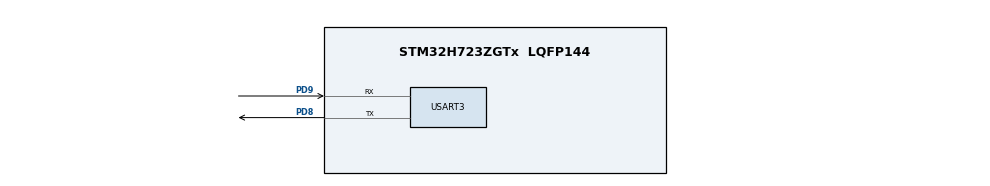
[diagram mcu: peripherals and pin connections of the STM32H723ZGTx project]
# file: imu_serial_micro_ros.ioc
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CORTEX_M7.AccessPermission_S-Cortex_Memory_Protection_Unit_Region1_Settings_S=MPU_REGION_FULL_ACCESS
CORTEX_M7.BaseAddress_S-Cortex_Memory_Protection_Unit_Region1_Settings_S=0x24000000
CORTEX_M7.CPU_DCache=Enabled
CORTEX_M7.CPU_ICache=Enabled
CORTEX_M7.Enable_S-Cortex_Memory_Protection_Unit_Region1_Settings_S=MPU_REGION_ENABLE
CORTEX_M7.Size_S-Cortex_Memory_Protection_Unit_Region1_Settings_S=MPU_REGION_SIZE_16KB
CORTEX_M7.TypeExtField_S-Cortex_Memory_Protection_Unit_Region1_Settings_S=MPU_TEX_LEVEL1
CORTEX_M7.default_mode_Activation=1
Dma.Request0=USART3_RX
Dma.Request1=USART3_TX
Dma.USART3_RX.0.Direction=DMA_PERIPH_TO_MEMORY
Dma.USART3_RX.0.EventEnable=DISABLE
Dma.USART3_RX.0.FIFOMode=DMA_FIFOMODE_DISABLE
Dma.USART3_RX.0.Instance=DMA1_Stream0
Dma.USART3_RX.0.MemDataAlignment=DMA_MDATAALIGN_BYTE
Dma.USART3_RX.0.MemInc=DMA_MINC_ENABLE
Dma.USART3_RX.0.Mode=DMA_CIRCULAR
Dma.USART3_RX.0.PeriphDataAlignment=DMA_PDATAALIGN_BYTE
Dma.USART3_RX.0.PeriphInc=DMA_PINC_DISABLE
Dma.USART3_RX.0.Polarity=HAL_DMAMUX_REQ_GEN_RISING
Dma.USART3_RX.0.Priority=DMA_PRIORITY_VERY_HIGH
Dma.USART3_RX.0.RequestNumber=1
Dma.USART3_RX.0.SignalID=NONE
Dma.USART3_RX.0.SyncEnable=DISABLE
Dma.USART3_RX.0.SyncPolarity=HAL_DMAMUX_SYNC_NO_EVENT
Dma.USART3_RX.0.SyncRequestNumber=1
Dma.USART3_RX.0.SyncSignalID=NONE
Dma.USART3_TX.1.Direction=DMA_MEMORY_TO_PERIPH
Dma.USART3_TX.1.EventEnable=DISABLE
Dma.USART3_TX.1.FIFOMode=DMA_FIFOMODE_DISABLE
Dma.USART3_TX.1.Instance=DMA1_Stream1
Dma.USART3_TX.1.MemDataAlignment=DMA_MDATAALIGN_BYTE
Dma.USART3_TX.1.MemInc=DMA_MINC_ENABLE
Dma.USART3_TX.1.Mode=DMA_NORMAL
Dma.USART3_TX.1.PeriphDataAlignment=DMA_PDATAALIGN_BYTE
Dma.USART3_TX.1.PeriphInc=DMA_PINC_DISABLE
Dma.USART3_TX.1.Polarity=HAL_DMAMUX_REQ_GEN_RISING
Dma.USART3_TX.1.Priority=DMA_PRIORITY_VERY_HIGH
Dma.USART3_TX.1.RequestNumber=1
Dma.USART3_TX.1.SignalID=NONE
Dma.USART3_TX.1.SyncEnable=DISABLE
Dma.USART3_TX.1.SyncPolarity=HAL_DMAMUX_SYNC_NO_EVENT
Dma.USART3_TX.1.SyncRequestNumber=1
Dma.USART3_TX.1.SyncSignalID=NONE
FREERTOS.Tasks01=defaultTask,24,3000,StartDefaultTask,Default,NULL,Dynamic,NULL,NULL
Mcu.Family=STM32H7
Mcu.Name=STM32H723ZGTx
Mcu.Package=LQFP144
NUCLEO-H723ZG.BUTTON=1
NUCLEO-H723ZG.LD1=true
NUCLEO-H723ZG.LD2=true
NUCLEO-H723ZG.LD3=true
NUCLEO-H723ZG.VCP=false
NVIC.DMA1_Stream0_IRQn=true\:5\:0\:false\:false\:true\:true\:false\:true\:true
NVIC.DMA1_Stream1_IRQn=true\:5\:0\:false\:false\:true\:true\:false\:true\:true
NVIC.EXTI15_10_IRQn=true\:5\:0\:false\:false\:true\:true\:false\:true\:true
NVIC.PriorityGroup=NVIC_PRIORITYGROUP_4
NVIC.TIM1_UP_IRQn=true\:15\:0\:false\:false\:true\:false\:false\:true\:true
NVIC.TimeBase=TIM1_UP_IRQn
NVIC.TimeBaseIP=TIM1
NVIC.USART3_IRQn=true\:5\:0\:false\:false\:true\:true\:true\:true\:true
PA13(JTMS/SWDIO).GPIO_Label=SWDIO
PA13(JTMS/SWDIO).Signal=DEBUG_JTMS-SWDIO
PA14(JTCK/SWCLK).GPIO_Label=SWCLK
PA14(JTCK/SWCLK).Signal=DEBUG_JTCK-SWCLK
PC14-OSC32_IN.Signal=RCC_OSC32_IN
PC15-OSC32_OUT.Signal=RCC_OSC32_OUT
PD8.Mode=Asynchronous
PD8.Signal=USART3_TX
PD9.Mode=Asynchronous
PD9.Signal=USART3_RX
PH0-OSC_IN.Mode=HSE-External-Oscillator
PH0-OSC_IN.Signal=RCC_OSC_IN
PH1-OSC_OUT.Mode=HSE-External-Oscillator
PH1-OSC_OUT.Signal=RCC_OSC_OUT
ProjectManager.HeapSize=0x200
ProjectManager.StackSize=0x400
ProjectManager.TargetToolchain=STM32CubeIDE
RCC.ADCFreq_Value=608000000
RCC.APB1Freq_Value=137500000
RCC.APB2Freq_Value=137500000
RCC.APB3Freq_Value=137500000
RCC.APB4Freq_Value=137500000
RCC.CortexFreq_Value=550000000
RCC.D1PPRE=RCC_APB3_DIV2
RCC.D2PPRE1=RCC_APB1_DIV2
RCC.D2PPRE2=RCC_APB2_DIV2
RCC.D3PPRE=RCC_APB4_DIV2
RCC.DIVM1=4
RCC.DIVM2=1
RCC.DIVN1=34
RCC.DIVN2=19
RCC.DIVP1=1
RCC.DIVQ1=4
RCC.HCLKFreq_Value=275000000
RCC.HPRE=RCC_HCLK_DIV2
RCC.HSE_VALUE=8000000
RCC.PLLFRACN=3072
RCC.SYSCLKFreq_VALUE=550000000
RCC.SYSCLKSource=RCC_SYSCLKSOURCE_PLLCLK
RCC.USBCLockSelection=RCC_USBCLKSOURCE_HSI48
RCC.USBFreq_Value=48000000
USART3.VirtualMode-Asynchronous=VM_ASYNC
VP_FREERTOS_VS_CMSIS_V2.Mode=CMSIS_V2
VP_MEMORYMAP_VS_MEMORYMAP.Mode=CurAppReg
VP_NUCLEO-H723ZG_VS_BSP_COMMON.Mode=COMMON
VP_SYS_VS_tim1.Mode=TIM1
board=NUCLEO-H723ZG

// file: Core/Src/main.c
/* USER CODE BEGIN Header */
/**
  ******************************************************************************
  * @file           : main.c
  * @brief          : Main program body
  ******************************************************************************
  * @attention
  *
  * Copyright (c) 2026 STMicroelectronics.
  * All rights reserved.
  *
  * This software is licensed under terms that can be found in the LICENSE file
  * in the root directory of this software component.
  * If no LICENSE file comes with this software, it is provided AS-IS.
  *
  ******************************************************************************
  */
/* USER CODE END Header */
#include "main.h"
#include "cmsis_os.h"
#include "dma.h"
#include "usart.h"
#include "gpio.h"

void SystemClock_Config(void);
static void MPU_Config(void);
void MX_FREERTOS_Init(void);

int main(void)
{

  /* MPU Configuration--------------------------------------------------------*/
  MPU_Config();

  /* Enable the CPU Cache */

  /* Enable I-Cache---------------------------------------------------------*/
  SCB_EnableICache();

  /* Enable D-Cache---------------------------------------------------------*/
  SCB_EnableDCache();

  /* MCU Configuration--------------------------------------------------------*/

  /* Reset of all peripherals, Initializes the Flash interface and the Systick. */
  HAL_Init();

  /* Configure the system clock */
  SystemClock_Config();

  /* Initialize all configured peripherals */
  MX_GPIO_Init();
  MX_DMA_Init();
  MX_USART3_UART_Init();

  /* Init scheduler */
  osKernelInitialize();  /* Call init function for freertos objects (in cmsis_os2.c) */
  MX_FREERTOS_Init();

  /* Initialize leds */
  BSP_LED_Init(LED_GREEN);
  BSP_LED_Init(LED_YELLOW);
  BSP_LED_Init(LED_RED);

  /* Initialize USER push-button, will be used to trigger an interrupt each time it's pressed.*/
  BSP_PB_Init(BUTTON_USER, BUTTON_MODE_EXTI);

  /* Start scheduler */
  osKernelStart();

  /* We should never get here as control is now taken by the scheduler */

  /* Infinite loop */
  while (1)
  {

  }
}

void SystemClock_Config(void)
{
  RCC_OscInitTypeDef RCC_OscInitStruct = {0};
  RCC_ClkInitTypeDef RCC_ClkInitStruct = {0};

  /** Supply configuration update enable
  */
  HAL_PWREx_ConfigSupply(PWR_LDO_SUPPLY);

  /** Configure the main internal regulator output voltage
  */
  __HAL_PWR_VOLTAGESCALING_CONFIG(PWR_REGULATOR_VOLTAGE_SCALE0);

  while(!__HAL_PWR_GET_FLAG(PWR_FLAG_VOSRDY)) {}

  /** Initializes the RCC Oscillators according to the specified parameters
  * in the RCC_OscInitTypeDef structure.
  */
  RCC_OscInitStruct.OscillatorType = RCC_OSCILLATORTYPE_HSI;
  RCC_OscInitStruct.HSIState = RCC_HSI_DIV1;
  RCC_OscInitStruct.HSICalibrationValue = 64;
  RCC_OscInitStruct.PLL.PLLState = RCC_PLL_ON;
  RCC_OscInitStruct.PLL.PLLSource = RCC_PLLSOURCE_HSI;
  RCC_OscInitStruct.PLL.PLLM = 4;
  RCC_OscInitStruct.PLL.PLLN = 34;
  RCC_OscInitStruct.PLL.PLLP = 1;
  RCC_OscInitStruct.PLL.PLLQ = 4;
  RCC_OscInitStruct.PLL.PLLR = 2;
  RCC_OscInitStruct.PLL.PLLRGE = RCC_PLL1VCIRANGE_3;
  RCC_OscInitStruct.PLL.PLLVCOSEL = RCC_PLL1VCOWIDE;
  RCC_OscInitStruct.PLL.PLLFRACN = 3072;
  if (HAL_RCC_OscConfig(&RCC_OscInitStruct) != HAL_OK)
  {
    Error_Handler();
  }

  /** Initializes the CPU, AHB and APB buses clocks
  */
  RCC_ClkInitStruct.ClockType = RCC_CLOCKTYPE_HCLK|RCC_CLOCKTYPE_SYSCLK
                              |RCC_CLOCKTYPE_PCLK1|RCC_CLOCKTYPE_PCLK2
                              |RCC_CLOCKTYPE_D3PCLK1|RCC_CLOCKTYPE_D1PCLK1;
  RCC_ClkInitStruct.SYSCLKSource = RCC_SYSCLKSOURCE_PLLCLK;
  RCC_ClkInitStruct.SYSCLKDivider = RCC_SYSCLK_DIV1;
  RCC_ClkInitStruct.AHBCLKDivider = RCC_HCLK_DIV2;
  RCC_ClkInitStruct.APB3CLKDivider = RCC_APB3_DIV2;
  RCC_ClkInitStruct.APB1CLKDivider = RCC_APB1_DIV2;
  RCC_ClkInitStruct.APB2CLKDivider = RCC_APB2_DIV2;
  RCC_ClkInitStruct.APB4CLKDivider = RCC_APB4_DIV2;

  if (HAL_RCC_ClockConfig(&RCC_ClkInitStruct, FLASH_LATENCY_3) != HAL_OK)
  {
    Error_Handler();
  }
}

 /* MPU Configuration */

void MPU_Config(void)
{
  MPU_Region_InitTypeDef MPU_InitStruct = {0};

  /* Disables the MPU */
  HAL_MPU_Disable();

  /** Initializes and configures the Region and the memory to be protected
  */
  MPU_InitStruct.Enable = MPU_REGION_ENABLE;
  MPU_InitStruct.Number = MPU_REGION_NUMBER0;
  MPU_InitStruct.BaseAddress = 0x0;
  MPU_InitStruct.Size = MPU_REGION_SIZE_4GB;
  MPU_InitStruct.SubRegionDisable = 0x87;
  MPU_InitStruct.TypeExtField = MPU_TEX_LEVEL0;
  MPU_InitStruct.AccessPermission = MPU_REGION_NO_ACCESS;
  MPU_InitStruct.DisableExec = MPU_INSTRUCTION_ACCESS_DISABLE;
  MPU_InitStruct.IsShareable = MPU_ACCESS_SHAREABLE;
  MPU_InitStruct.IsCacheable = MPU_ACCESS_NOT_CACHEABLE;
  MPU_InitStruct.IsBufferable = MPU_ACCESS_NOT_BUFFERABLE;

  HAL_MPU_ConfigRegion(&MPU_InitStruct);

  /** Initializes and configures the Region and the memory to be protected
  */
  MPU_InitStruct.Number = MPU_REGION_NUMBER1;
  MPU_InitStruct.BaseAddress = 0x24000000;
  MPU_InitStruct.Size = MPU_REGION_SIZE_16KB;
  MPU_InitStruct.SubRegionDisable = 0x0;
  MPU_InitStruct.TypeExtField = MPU_TEX_LEVEL1;
  MPU_InitStruct.AccessPermission = MPU_REGION_FULL_ACCESS;
  MPU_InitStruct.DisableExec = MPU_INSTRUCTION_ACCESS_ENABLE;
  MPU_InitStruct.IsShareable = MPU_ACCESS_NOT_SHAREABLE;

  HAL_MPU_ConfigRegion(&MPU_InitStruct);
  /* Enables the MPU */
  HAL_MPU_Enable(MPU_PRIVILEGED_DEFAULT);

}

void HAL_TIM_PeriodElapsedCallback(TIM_HandleTypeDef *htim)
{
  if (htim->Instance == TIM1)
  {
    HAL_IncTick();
  }
}

void Error_Handler(void)
{
  __disable_irq();
  while (1)
  {
  }
}

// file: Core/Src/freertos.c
/* USER CODE BEGIN Header */
/**
  ******************************************************************************
  * File Name          : freertos.c
  * Description        : Code for freertos applications
  ******************************************************************************
  * @attention
  *
  * Copyright (c) 2026 STMicroelectronics.
  * All rights reserved.
  *
  * This software is licensed under terms that can be found in the LICENSE file
  * in the root directory of this software component.
  * If no LICENSE file comes with this software, it is provided AS-IS.
  *
  ******************************************************************************
  */
/* USER CODE END Header */

#include "FreeRTOS.h"
#include "task.h"
#include "main.h"
#include "cmsis_os.h"

/* USER CODE BEGIN Includes */
#include "usart.h"
#include <rcl/rcl.h>
#include <rcl/error_handling.h>
#include <rclc/rclc.h>
#include <rclc/executor.h>
#include <uxr/client/transport.h>
#include <rmw_microxrcedds_c/config.h>
#include <rmw_microros/rmw_microros.h>

#include <std_msgs/msg/int32.h>
#include <geometry_msgs/msg/accel.h>
#include <sensor_msgs/msg/nav_sat_fix.h>
/* USER CODE END Includes */

/* Definitions for defaultTask */
osThreadId_t defaultTaskHandle;
const osThreadAttr_t defaultTask_attributes = {
  .name = "defaultTask",
  .stack_size = 3000 * 4,
  .priority = (osPriority_t) osPriorityNormal,
};

/* USER CODE BEGIN FunctionPrototypes */
bool cubemx_transport_open(struct uxrCustomTransport * transport);
bool cubemx_transport_close(struct uxrCustomTransport * transport);
size_t cubemx_transport_write(struct uxrCustomTransport* transport, const uint8_t * buf, size_t len, uint8_t * err);
size_t cubemx_transport_read(struct uxrCustomTransport* transport, uint8_t* buf, size_t len, int timeout, uint8_t* err);

void * microros_allocate(size_t size, void * state);
void microros_deallocate(void * pointer, void * state);
void * microros_reallocate(void * pointer, size_t size, void * state);
void * microros_zero_allocate(size_t number_of_elements, size_t size_of_element, void * state);
/* USER CODE END FunctionPrototypes */

void StartDefaultTask(void *argument);

void MX_FREERTOS_Init(void); /* (MISRA C 2004 rule 8.1) */

void MX_FREERTOS_Init(void) {

  /* Create the thread(s) */
  /* creation of defaultTask */
  defaultTaskHandle = osThreadNew(StartDefaultTask, NULL, &defaultTask_attributes);

}

void StartDefaultTask(void *argument)
{
  /* USER CODE BEGIN StartDefaultTask */
  /* Infinite loop */

	  // micro-ROS configuration

	  rmw_uros_set_custom_transport(
	    true,
	    (void *) &huart3,
	    cubemx_transport_open,
	    cubemx_transport_close,
	    cubemx_transport_write,
	    cubemx_transport_read);

	  rcl_allocator_t freeRTOS_allocator = rcutils_get_zero_initialized_allocator();
	  freeRTOS_allocator.allocate = microros_allocate;
	  freeRTOS_allocator.deallocate = microros_deallocate;
	  freeRTOS_allocator.reallocate = microros_reallocate;
	  freeRTOS_allocator.zero_allocate =  microros_zero_allocate;

	  if (!rcutils_set_default_allocator(&freeRTOS_allocator)) {
	      printf("Error on default allocators (line %d)\n", __LINE__);
	  }

	  // micro-ROS app

	  rcl_publisher_t publisher;
    rcl_publisher_t acc_publisher;
    rcl_publisher_t gps_publisher;
    std_msgs__msg__Int32 msg;
    geometry_msgs__msg__Accel acc_msg;
    sensor_msgs__msg__NavSatFix gps_msg;
	  rclc_support_t support;
	  rcl_allocator_t allocator;
	  rcl_node_t node;

	  allocator = rcl_get_default_allocator();

	  //create init_options
	  rclc_support_init(&support, 0, NULL, &allocator);

	  // create node
	  rclc_node_init_default(&node, "imu_data_node", "", &support);

	  // create publisher
	  rclc_publisher_init_default(
	    &publisher,
	    &node,
	    ROSIDL_GET_MSG_TYPE_SUPPORT(std_msgs, msg, Int32),
	    "acc_publisher");

    rclc_publisher_init_default(&acc_publisher, &node,
    ROSIDL_GET_MSG_TYPE_SUPPORT(geometry_msgs, msg, Accel), "imu_acc");

    rclc_publisher_init_default(&gps_publisher, &node,
    ROSIDL_GET_MSG_TYPE_SUPPORT(sensor_msgs, msg, NavSatFix), "gps_fix");

	  msg.data = 0;
	  acc_msg.linear.z = 9000;
	  acc_msg.linear.x = 300;
	  acc_msg.linear.y = 120;
	  sensor_msgs__msg__NavSatFix__init(&gps_msg);
	  gps_msg.latitude  = 30.0;
	  gps_msg.longitude = 10.0;
	  gps_msg.altitude  = 0.0;
	  gps_msg.status.status = 0;
	  for(;;)
	  {
	    rcl_ret_t ret = rcl_publish(&publisher, &msg, NULL);
	    if (ret != RCL_RET_OK)
	    {
	      printf("Error publishing (line %d)\n", __LINE__);
	    }
	    rcl_ret_t ret_acc = rcl_publish(&acc_publisher, &acc_msg, NULL);
	    if (ret_acc != RCL_RET_OK)
	    {
	      printf("Error publishing Acc (line %d)\n", __LINE__);
	    }

	    rcl_ret_t ret_gps = rcl_publish(&gps_publisher, &gps_msg, NULL);
	    if (ret_gps != RCL_RET_OK)
	    {
	      printf("Error publishing GPS (line %d)\n", __LINE__);
	    }
      gps_msg.status.status++;
	    msg.data++;
	    osDelay(10);
	  }
  /* USER CODE END StartDefaultTask */
}
